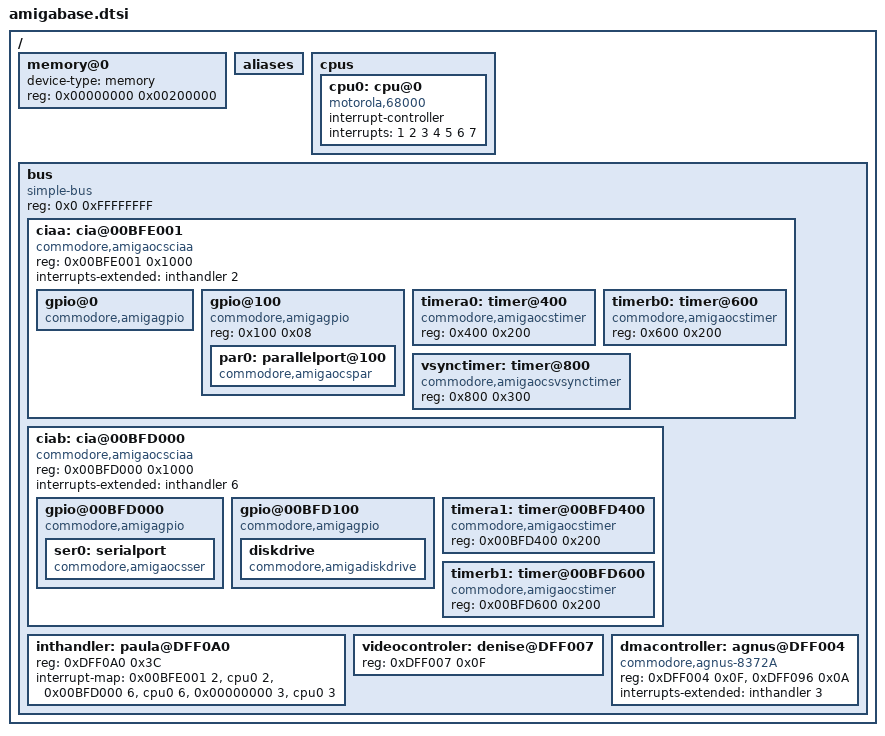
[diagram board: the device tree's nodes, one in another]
/* Represents a Rev 6 A500*/

/ {
	memory@0 {
		device-type = "memory";
		reg = <0x00000000 0x00200000>; // Chip RAM or System ROM Overlay
		//<0x00200000 0x00800000>; // Fast RAM or Zorro II and Credit Card Memory
		//<0x40000000 0x40000000>; // Zorro III space
	};
	
	aliases {
		
	};
	
	cpus {
		cpu0: cpu@0{
			compatible = "motorola,68000";
			device_type = "cpu";
			#interrupts-cells = <1>;
			interrupt-controller;
			interrupts = <1 2 3 4 5 6 7>;
		};
	};
	
	bus {
		compatible = "simple-bus";
		reg = <0x0 0xFFFFFFFF>;
		#address-cells = <1>;
		#size-cells = <1>;
		ranges;
		
		ciaa: cia@00BFE001 {
			compatible = "commodore,amigaocsciaa";
			reg = <0x00BFE001 0x1000>;
			#address-cells = <1>;
			#size-cells = <1>;
			interrupts-extended = <&inthandler 2>;
			ranges = <0x0 0xBFE001 0x1000>;
			gpio@0{
				compatible = "commodore,amigagpio";
			};
			gpio@100{
				reg = <0x100 0x08>;
				compatible = "commodore,amigagpio";
				ranges;
				par0: parallelport@100{
					compatible = "commodore,amigaocspar";
					ranges = <0x0 0x100 0x08>;
				};
			};
			timera0: timer@400{
				compatible = "commodore,amigaocstimer";
				reg = <0x400 0x200>;
			};
			timerb0: timer@600{
				compatible = "commodore,amigaocstimer";
				reg = <0x600 0x200>;
			};
			vsynctimer: timer@800{
				compatible = "commodore,amigaocsvsynctimer";
				reg = <0x800 0x300>;
			};
		};
		
		ciab: cia@00BFD000{
			compatible = "commodore,amigaocsciaa";
			reg = <0x00BFD000 0x1000>;
			#address-cells = <1>;
			#size-cells = <1>;
			interrupts-extended = <&inthandler 6>;
			ranges;
			gpio@00BFD000{
				compatible = "commodore,amigagpio";
				ser0: serialport{
					compatible = "commodore,amigaocsser";
				};
			};
			gpio@00BFD100{
				compatible = "commodore,amigagpio";
				diskdrive{
					compatible = "commodore,amigadiskdrive";
				};
			};
			timera1: timer@00BFD400{
				compatible = "commodore,amigaocstimer";
				reg = <0x00BFD400 0x200>;
			};
			
			timerb1: timer@00BFD600{
				compatible = "commodore,amigaocstimer";
				reg = <0x00BFD600 0x200>;
			};
		};
		
		inthandler: paula@DFF0A0{
			reg = <0xDFF0A0 0x3C>; // Audio registers
			#interrupts-cells = <1>;
			interrupt-map = <0x00BFE001 2 &cpu0 2>,
							<0x00BFD000 6 &cpu0 6>,
							<0x00000000 3 &cpu0 3>;

		};
		
		videocontroler: denise@DFF007{
			reg = <0xDFF007 0x0F>; // Denise ID register
		};
		
		dmacontroller: agnus@DFF004{
			reg = <0xDFF004 0x0F>, // VPOSR register
					<0xDFF096 0x0A>; // DMA registers
			compatible = "commodore,agnus-8372A";
			interrupts-extended = <&inthandler 3>;
		};
	};
};
